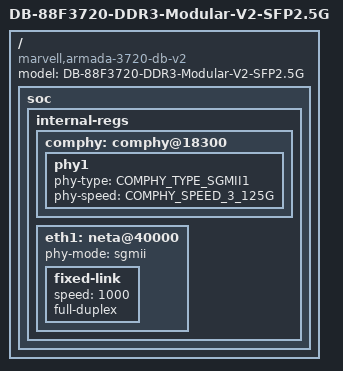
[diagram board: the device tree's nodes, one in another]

#include "armada-3720-db.dts"

/* detail board setup:
 * Pcie Jumper slot	:	DB-88F3720-PCIe-mPCIe-Jumper
 * SGMII module slot	:	DB-88F3720-SerDes-Jumper
 * RGMII module slot	:	DB-88F3720-PHY module
 * eMMC slot		:	DB-88F3720-eMMC_NAND module
 * SDIO slot		:	DB-88F3720-SDcard module
 *
 * PHY0 (USB3/SGMII1)	:	SGMII1_Ethernet via SFP2.5G (1 Lane)
 * PHY1 (PCIe/SGMII0)	:	PCIe (WiFi via mini_PCIe module)
 * PHY2 (SATA)		:	SATA
 * RGMII		:	Ethernet via PHY (1 Lane)
 * USB2 Port 0		:	USB2 only
 * USB2 Port 1		:	USB2 Host
 * eMMC*		:	eMMC NAND
 * SDIO*		:	SD card
 * BOOT device*		:	SPI Flash
*/

/ {
	model = "DB-88F3720-DDR3-Modular-V2-SFP2.5G";
	compatible = "marvell,armada-3720-db-v2", "marvell,armada-3720";

	soc {
		internal-regs {
			comphy: comphy@18300 {
				phy1 {
					phy-type = <COMPHY_TYPE_SGMII1>;
					phy-speed = <COMPHY_SPEED_3_125G>;
				};
			};
			eth1: neta@40000 {
				status = "okay";
				phy-mode = "sgmii";
				fixed-link {
					/* Here "speed" is set to 1000, GBE MAC is running in 1G mode,
					 * but the actuall PHY speed may be 1 Gbps or 2.5 Gbps,
					 * it's up to the corresponding SERDES speed in comphy node.
					 * If SERDES speed is set to 3.125G, it implies sgmii 2.5 Gbps;
					 * if SERDES speed is set to 1.25G, it implies sgmii 1 Gbps. */
					speed = <1000>;
					full-duplex;
				};
			};
		};
	};
};
